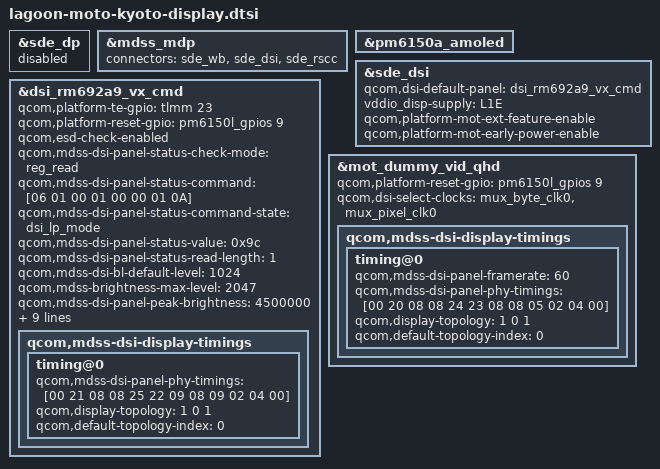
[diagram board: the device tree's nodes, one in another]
/* Copyright (c) 2019, The Linux Foundation. All rights reserved.
 *
 * This program is free software; you can redistribute it and/or modify
 * it under the terms of the GNU General Public License version 2 and
 * only version 2 as published by the Free Software Foundation.
 *
 * This program is distributed in the hope that it will be useful,
 * but WITHOUT ANY WARRANTY; without even the implied warranty of
 * MERCHANTABILITY or FITNESS FOR A PARTICULAR PURPOSE.  See the
 * GNU General Public License for more details.
 */
//#include <dt-bindings/regulator/qcom,rpmh-regulator-levels.h>
#include "dsi-panel-mot-dummy-qhd-video.dtsi"
#include "lagoon-sde-display.dtsi"
#include "dsi-panel-mot-visionox-rm692a9-667-1080p-cmd.dtsi"

&sde_dp {
	status = "disabled";
};

&mdss_mdp {
	connectors = <&sde_wb &sde_dsi &sde_rscc>;
};

&pm6150a_amoled {
	status = "ok";
};

&sde_dsi {
	/delete-property/ qcom,dsi-default-panel;
	qcom,dsi-default-panel = <&dsi_rm692a9_vx_cmd>;

	vddio_disp-supply = <&L1E>;

	qcom,platform-mot-ext-feature-enable;
	qcom,platform-mot-early-power-enable;
};

&dsi_rm692a9_vx_cmd {
	qcom,platform-te-gpio = <&tlmm 23 0>;
	qcom,platform-reset-gpio = <&pm6150l_gpios 9 0>;

	qcom,esd-check-enabled;
	qcom,mdss-dsi-panel-status-check-mode = "reg_read";
	qcom,mdss-dsi-panel-status-command = [06 01 00 01 00 00 01 0A];
	qcom,mdss-dsi-panel-status-command-state = "dsi_lp_mode";
	qcom,mdss-dsi-panel-status-value = <0x9c>;
	qcom,mdss-dsi-panel-status-read-length = <1>;

	qcom,mdss-dsi-bl-default-level = <1024>;
	qcom,mdss-brightness-max-level = <2047>;

        qcom,mdss-dsi-panel-peak-brightness = <4500000>;
        qcom,mdss-dsi-panel-blackness-level = <3000>;

	qcom,dsi-select-clocks = "mux_byte_clk0", "mux_pixel_clk0",
				"src_byte_clk0", "src_pixel_clk0",
				"shadow_byte_clk0", "shadow_pixel_clk0";
	qcom,panel-supply-entries = <&dsi_panel_pwr_supply>;
	qcom,mdss-dsi-t-clk-post = <0x0E>;
	qcom,mdss-dsi-t-clk-pre = <0x37>;
	qcom,mdss-dsi-display-timings {
		timing@0 {
			qcom,mdss-dsi-panel-phy-timings = [00 21 08 08 25 22 09
							08 09 02 04 00];
			qcom,display-topology = <1 0 1>;
			qcom,default-topology-index = <0>;
		};
	};
};

&mot_dummy_vid_qhd {
	qcom,platform-reset-gpio = <&pm6150l_gpios 9 0>;

	qcom,dsi-select-clocks = "mux_byte_clk0", "mux_pixel_clk0";
	qcom,mdss-dsi-display-timings {
		timing@0 {
			qcom,mdss-dsi-panel-framerate = <60>;
			qcom,mdss-dsi-panel-phy-timings = [00 20 08 08 24 23 08
							08 05 02 04 00];
			qcom,display-topology = <1 0 1>;
			qcom,default-topology-index = <0>;
		};
	};
};
